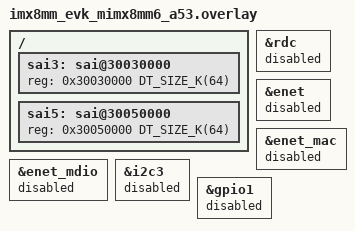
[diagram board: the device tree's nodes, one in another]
/*
 * Copyright 2024-2025 NXP
 *
 * SPDX-License-Identifier: BSD-3-Clause
 */

/ {
	sai3: sai@30030000 {
		reg = <0x30030000 DT_SIZE_K(64)>;
	};

	sai5: sai@30050000 {
		reg = <0x30050000 DT_SIZE_K(64)>;
	};
};

&rdc {
	status = "disabled";
};

&enet {
	status = "disabled";
};

&enet_mac {
	status = "disabled";
};

&enet_mdio {
	status = "disabled";
};

&i2c3 {
	status = "disabled";
};

&gpio1 {
	status = "disabled";
};
